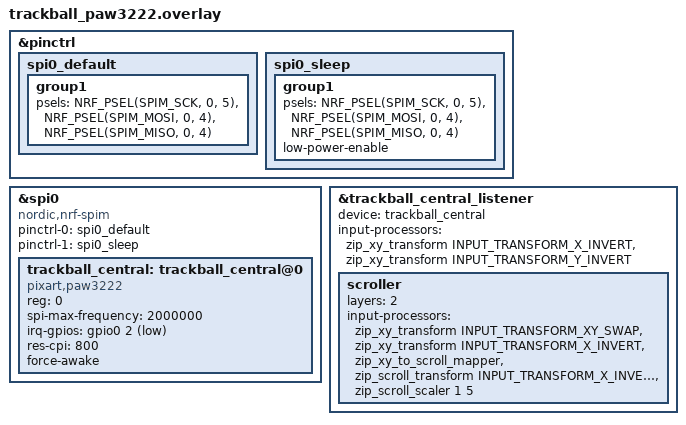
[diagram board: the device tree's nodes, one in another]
#include <input/processors.dtsi>
#include <dt-bindings/zmk/input_transform.h>
#include <zephyr/dt-bindings/input/input-event-codes.h>

&pinctrl {
    spi0_default: spi0_default {
        group1 {
            psels = <NRF_PSEL(SPIM_SCK, 0, 5)>,
                <NRF_PSEL(SPIM_MOSI, 0, 4)>,
                <NRF_PSEL(SPIM_MISO, 0, 4)>;
        };
    };

    spi0_sleep: spi0_sleep {
        group1 {
            psels = <NRF_PSEL(SPIM_SCK, 0, 5)>,
                <NRF_PSEL(SPIM_MOSI, 0, 4)>,
                <NRF_PSEL(SPIM_MISO, 0, 4)>;
            low-power-enable;
        };
    };
};

&spi0 {
    status = "okay";
    compatible = "nordic,nrf-spim";
    pinctrl-0 = <&spi0_default>;
    pinctrl-1 = <&spi0_sleep>;
    pinctrl-names = "default", "sleep";
    // cs-gpios = <&gpio0 9 GPIO_ACTIVE_LOW>; GND

    trackball_central: trackball_central@0 {
        status = "okay";
        compatible = "pixart,paw3222";
        reg = <0>;
        spi-max-frequency = <2000000>;
        irq-gpios = <&gpio0 2 (GPIO_ACTIVE_LOW | GPIO_PULL_UP)>;
        res-cpi = <800>;
        force-awake;
    };
};

&trackball_central_listener {
    status = "okay";
    device = <&trackball_central>;
    input-processors =
        <&zip_xy_transform INPUT_TRANSFORM_X_INVERT>,
        <&zip_xy_transform INPUT_TRANSFORM_Y_INVERT>;

    scroller {
        layers = <2>;
        input-processors =
            <&zip_xy_transform INPUT_TRANSFORM_XY_SWAP>,
            <&zip_xy_transform INPUT_TRANSFORM_X_INVERT>,
            <&zip_xy_to_scroll_mapper>,
            <&zip_scroll_transform INPUT_TRANSFORM_X_INVERT>,
            <&zip_scroll_scaler 1 5>;
    };
};
